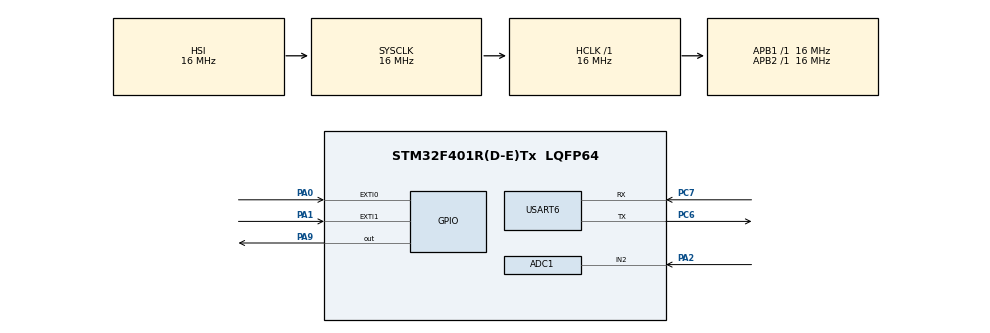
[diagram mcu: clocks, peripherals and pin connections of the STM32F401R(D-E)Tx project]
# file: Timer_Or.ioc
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ADC1.Channel-0\#ChannelRegularConversion=ADC_CHANNEL_2
ADC1.NbrOfConversionFlag=1
ADC1.Rank-0\#ChannelRegularConversion=1
ADC1.SamplingTime-0\#ChannelRegularConversion=ADC_SAMPLETIME_3CYCLES
ADC1.master=1
Mcu.Family=STM32F4
Mcu.Name=STM32F401R(D-E)Tx
Mcu.Package=LQFP64
NVIC.ADC_IRQn=true\:0\:0\:false\:false\:true\:true\:true\:true
NVIC.EXTI0_IRQn=true\:0\:0\:false\:false\:true\:true\:true\:true
NVIC.EXTI1_IRQn=true\:0\:0\:false\:false\:true\:true\:true\:true
NVIC.PriorityGroup=NVIC_PRIORITYGROUP_4
NVIC.TIM1_UP_TIM10_IRQn=true\:0\:0\:false\:false\:true\:true\:true\:true
NVIC.USART6_IRQn=true\:0\:0\:false\:false\:true\:true\:true\:true
PA0-WKUP.Signal=GPXTI0
PA1.Signal=GPXTI1
PA2.Signal=ADCx_IN2
PA9.Signal=GPIO_Output
PC6.Mode=Asynchronous
PC6.Signal=USART6_TX
PC7.Mode=Asynchronous
PC7.Signal=USART6_RX
ProjectManager.HeapSize=0x200
ProjectManager.StackSize=0x400
ProjectManager.TargetToolchain=STM32CubeIDE
RCC.48MHZClocksFreq_Value=48000000
RCC.AHBFreq_Value=16000000
RCC.APB1Freq_Value=16000000
RCC.APB1TimFreq_Value=16000000
RCC.APB2Freq_Value=16000000
RCC.APB2TimFreq_Value=16000000
RCC.CortexFreq_Value=16000000
RCC.HCLKFreq_Value=16000000
RCC.HSE_VALUE=25000000
RCC.HSI_VALUE=16000000
RCC.LSE_VALUE=32768
RCC.SYSCLKFreq_VALUE=16000000
RCC.VCOOutputFreq_Value=192000000
SH.ADCx_IN2.0=ADC1_IN2,IN2
TIM10.AutoReloadPreload=TIM_AUTORELOAD_PRELOAD_ENABLE
TIM10.Period=999
TIM10.Prescaler=7999
USART6.VirtualMode=VM_ASYNC
VP_TIM10_VS_ClockSourceINT.Mode=Enable_Timer
board=custom

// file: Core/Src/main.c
/* USER CODE BEGIN Header */
/**
  ******************************************************************************
  * @file           : main.c
  * @brief          : Main program body
  ******************************************************************************
  * @attention
  *
  * Copyright (c) 2022 STMicroelectronics.
  * All rights reserved.
  *
  * This software is licensed under terms that can be found in the LICENSE file
  * in the root directory of this software component.
  * If no LICENSE file comes with this software, it is provided AS-IS.
  *
  ******************************************************************************
  */
/* USER CODE END Header */
#include "main.h"

ADC_HandleTypeDef hadc1;

TIM_HandleTypeDef htim10;

UART_HandleTypeDef huart6;

void SystemClock_Config(void);
static void MX_GPIO_Init(void);
static void MX_ADC1_Init(void);
static void MX_USART6_UART_Init(void);
static void MX_TIM10_Init(void);

int main(void)
{

  /* MCU Configuration--------------------------------------------------------*/

  /* Reset of all peripherals, Initializes the Flash interface and the Systick. */
  HAL_Init();

  /* Configure the system clock */
  SystemClock_Config();

  /* Initialize all configured peripherals */
  MX_GPIO_Init();
  MX_ADC1_Init();
  MX_USART6_UART_Init();
  MX_TIM10_Init();
  /* USER CODE BEGIN 2 */
HAL_TIM_Base_Start_IT(&htim10);
  /* USER CODE END 2 */

  /* Infinite loop */
  while (1)
  {

  }
}

void SystemClock_Config(void)
{
  RCC_OscInitTypeDef RCC_OscInitStruct = {0};
  RCC_ClkInitTypeDef RCC_ClkInitStruct = {0};

  /** Configure the main internal regulator output voltage
  */
  __HAL_RCC_PWR_CLK_ENABLE();
  __HAL_PWR_VOLTAGESCALING_CONFIG(PWR_REGULATOR_VOLTAGE_SCALE2);

  /** Initializes the RCC Oscillators according to the specified parameters
  * in the RCC_OscInitTypeDef structure.
  */
  RCC_OscInitStruct.OscillatorType = RCC_OSCILLATORTYPE_HSI;
  RCC_OscInitStruct.HSIState = RCC_HSI_ON;
  RCC_OscInitStruct.HSICalibrationValue = RCC_HSICALIBRATION_DEFAULT;
  RCC_OscInitStruct.PLL.PLLState = RCC_PLL_NONE;
  if (HAL_RCC_OscConfig(&RCC_OscInitStruct) != HAL_OK)
  {
    Error_Handler();
  }

  /** Initializes the CPU, AHB and APB buses clocks
  */
  RCC_ClkInitStruct.ClockType = RCC_CLOCKTYPE_HCLK|RCC_CLOCKTYPE_SYSCLK
                              |RCC_CLOCKTYPE_PCLK1|RCC_CLOCKTYPE_PCLK2;
  RCC_ClkInitStruct.SYSCLKSource = RCC_SYSCLKSOURCE_HSI;
  RCC_ClkInitStruct.AHBCLKDivider = RCC_SYSCLK_DIV1;
  RCC_ClkInitStruct.APB1CLKDivider = RCC_HCLK_DIV1;
  RCC_ClkInitStruct.APB2CLKDivider = RCC_HCLK_DIV1;

  if (HAL_RCC_ClockConfig(&RCC_ClkInitStruct, FLASH_LATENCY_0) != HAL_OK)
  {
    Error_Handler();
  }
}

static void MX_ADC1_Init(void)
{

  ADC_ChannelConfTypeDef sConfig = {0};

  /** Configure the global features of the ADC (Clock, Resolution, Data Alignment and number of conversion)
  */
  hadc1.Instance = ADC1;
  hadc1.Init.ClockPrescaler = ADC_CLOCK_SYNC_PCLK_DIV2;
  hadc1.Init.Resolution = ADC_RESOLUTION_12B;
  hadc1.Init.ScanConvMode = DISABLE;
  hadc1.Init.ContinuousConvMode = DISABLE;
  hadc1.Init.DiscontinuousConvMode = DISABLE;
  hadc1.Init.ExternalTrigConvEdge = ADC_EXTERNALTRIGCONVEDGE_NONE;
  hadc1.Init.ExternalTrigConv = ADC_SOFTWARE_START;
  hadc1.Init.DataAlign = ADC_DATAALIGN_RIGHT;
  hadc1.Init.NbrOfConversion = 1;
  hadc1.Init.DMAContinuousRequests = DISABLE;
  hadc1.Init.EOCSelection = ADC_EOC_SINGLE_CONV;
  if (HAL_ADC_Init(&hadc1) != HAL_OK)
  {
    Error_Handler();
  }

  /** Configure for the selected ADC regular channel its corresponding rank in the sequencer and its sample time.
  */
  sConfig.Channel = ADC_CHANNEL_2;
  sConfig.Rank = 1;
  sConfig.SamplingTime = ADC_SAMPLETIME_3CYCLES;
  if (HAL_ADC_ConfigChannel(&hadc1, &sConfig) != HAL_OK)
  {
    Error_Handler();
  }

}

static void MX_TIM10_Init(void)
{

  htim10.Instance = TIM10;
  htim10.Init.Prescaler = 7999;
  htim10.Init.CounterMode = TIM_COUNTERMODE_UP;
  htim10.Init.Period = 999;
  htim10.Init.ClockDivision = TIM_CLOCKDIVISION_DIV1;
  htim10.Init.AutoReloadPreload = TIM_AUTORELOAD_PRELOAD_ENABLE;
  if (HAL_TIM_Base_Init(&htim10) != HAL_OK)
  {
    Error_Handler();
  }

}

static void MX_USART6_UART_Init(void)
{

  huart6.Instance = USART6;
  huart6.Init.BaudRate = 115200;
  huart6.Init.WordLength = UART_WORDLENGTH_8B;
  huart6.Init.StopBits = UART_STOPBITS_1;
  huart6.Init.Parity = UART_PARITY_NONE;
  huart6.Init.Mode = UART_MODE_TX_RX;
  huart6.Init.HwFlowCtl = UART_HWCONTROL_NONE;
  huart6.Init.OverSampling = UART_OVERSAMPLING_16;
  if (HAL_UART_Init(&huart6) != HAL_OK)
  {
    Error_Handler();
  }

}

static void MX_GPIO_Init(void)
{
  GPIO_InitTypeDef GPIO_InitStruct = {0};

  /* GPIO Ports Clock Enable */
  __HAL_RCC_GPIOA_CLK_ENABLE();
  __HAL_RCC_GPIOC_CLK_ENABLE();

  /*Configure GPIO pin Output Level */
  HAL_GPIO_WritePin(GPIOA, GPIO_PIN_9, GPIO_PIN_RESET);

  /*Configure GPIO pins : PA0 PA1 */
  GPIO_InitStruct.Pin = GPIO_PIN_0|GPIO_PIN_1;
  GPIO_InitStruct.Mode = GPIO_MODE_IT_RISING;
  GPIO_InitStruct.Pull = GPIO_NOPULL;
  HAL_GPIO_Init(GPIOA, &GPIO_InitStruct);

  /*Configure GPIO pin : PA9 */
  GPIO_InitStruct.Pin = GPIO_PIN_9;
  GPIO_InitStruct.Mode = GPIO_MODE_OUTPUT_PP;
  GPIO_InitStruct.Pull = GPIO_NOPULL;
  GPIO_InitStruct.Speed = GPIO_SPEED_FREQ_LOW;
  HAL_GPIO_Init(GPIOA, &GPIO_InitStruct);

  /* EXTI interrupt init*/
  HAL_NVIC_SetPriority(EXTI0_IRQn, 0, 0);
  HAL_NVIC_EnableIRQ(EXTI0_IRQn);

  HAL_NVIC_SetPriority(EXTI1_IRQn, 0, 0);
  HAL_NVIC_EnableIRQ(EXTI1_IRQn);

}

/* USER CODE BEGIN 4 */
void HAL_TIM_PeriodElapsedCallback(TIM_HandleTypeDef *htim){

	if(htim->Instance==TIM10){
     HAL_GPIO_TogglePin(GPIOA, GPIO_PIN_9);

	}
}

/* USER CODE END 4 */

void Error_Handler(void)
{
  __disable_irq();
  while (1)
  {
  }
}
